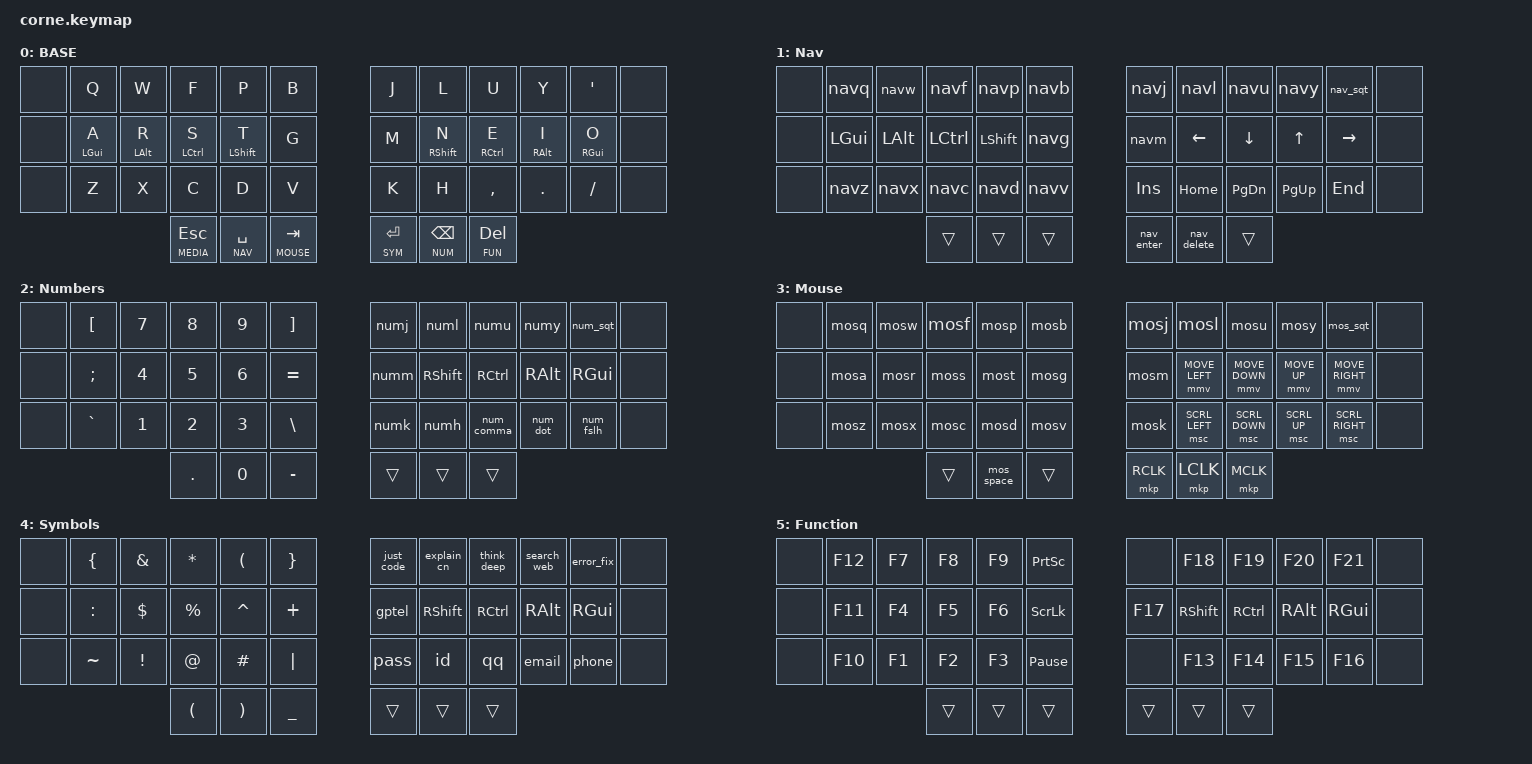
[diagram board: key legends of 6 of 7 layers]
#include <behaviors.dtsi>
#include <dt-bindings/zmk/keys.h>
#include <dt-bindings/zmk/outputs.h>
#include <dt-bindings/zmk/pointing.h>

#define ZMK_POINTING_DEFAULT_MOVE_VAL 450  // default: 600
#define ZMK_POINTING_DEFAULT_SCRL_VAL 20   // default: 10

#define BASE   0
#define NAV    1
#define NUM    2
#define MOUSE  3
#define SYM    4
#define FUN    5
#define MEDIA  6

#define QUICK_TAP_MS 145

&lt {
    flavor = "balanced";
    tapping-term-ms = <200>;
    quick-tap-ms = <QUICK_TAP_MS>;
};

&mmv {
    x-input-code             = <INPUT_REL_X>;
    y-input-code             = <INPUT_REL_Y>;
    time-to-max-speed-ms     = <0>;
    acceleration-exponent    = <0>;
};

&msc {
    x-input-code             = <INPUT_REL_HWHEEL>;
    y-input-code             = <INPUT_REL_WHEEL>;
    time-to-max-speed-ms     = <0>;
    acceleration-exponent    = <0>;
};

 / {

    macros {
    /* q  -> C-M-@  (Ctrl + Meta + @) */
    navq: navq {
        compatible = "zmk,behavior-macro";
        #binding-cells = <0>;
        bindings
        = <&macro_press   &kp LCTRL>
          , <&macro_tap     &kp LA(AT)>
          , <&macro_release &kp LCTRL>;
    };

    navw: navw {
        compatible = "zmk,behavior-macro";
        #binding-cells = <0>;
        /* w -> M-@ (Meta + @) */
        bindings = <&macro_tap     &kp LA(AT)>;
    };

    /* f -> C-M-h (Ctrl + Meta + h) */
    navf: navf {
        compatible = "zmk,behavior-macro";
        #binding-cells = <0>;
        bindings
        = <&macro_press   &kp LCTRL>
          , <&macro_tap     &kp LA(H)>
          , <&macro_release &kp LCTRL>;
    };

    /* p -> C-x h  (Ctrl+x then h) */
    navp: navp {
        compatible = "zmk,behavior-macro";
        #binding-cells = <0>;
        bindings
        = <&macro_tap     &kp LC(N)>
          , <&macro_tap     &kp H>;
    };

    /* b -> C-c, C-~, then B */
    navb: navb {
        compatible = "zmk,behavior-macro";
        #binding-cells = <0>;
        bindings
        = <&macro_tap     &kp LC(C)>
          , <&macro_tap     &kp LC(TILDE)>
          , <&macro_tap     &kp B>;
    };
////////
    navj: navj {
        compatible = "zmk,behavior-macro";
        #binding-cells = <0>;
        bindings
        = <&macro_tap     &kp LC(C)>
          , <&macro_tap     &kp LC(TILDE)>
          , <&macro_tap     &kp J>;
    };

    navl: navl {
        compatible = "zmk,behavior-macro";
        #binding-cells = <0>;
        bindings
        = <&macro_tap     &kp LC(C)>
          , <&macro_tap     &kp LC(TILDE)>
          , <&macro_tap     &kp L>;
    };

    navu: navu {
        compatible = "zmk,behavior-macro";
        #binding-cells = <0>;
        bindings
        = <&macro_tap     &kp LC(C)>
          , <&macro_tap     &kp LC(TILDE)>
          , <&macro_tap     &kp U>;
    };

    navy: navy {
        compatible = "zmk,behavior-macro";
        #binding-cells = <0>;
        bindings
        = <&macro_tap     &kp LC(C)>
          , <&macro_tap     &kp LC(TILDE)>
          , <&macro_tap     &kp Y>;
    };

    nav_sqt: nav_sqt {
        compatible = "zmk,behavior-macro";
        #binding-cells = <0>;
        bindings
        = <&macro_tap     &kp LC(C)>
          , <&macro_tap     &kp LC(TILDE)>
          , <&macro_tap     &kp SQT>;
    };


/////
    /* g: C-c, C-~, then g */
    navg: navg {
        compatible = "zmk,behavior-macro";
        #binding-cells = <0>;
        bindings
        = <&macro_tap     &kp LC(C)>
          , <&macro_tap     &kp LC(TILDE)>
          , <&macro_tap     &kp G>;
    };

    /* m: C-c, C-~, then m */
    navm: navm {
        compatible = "zmk,behavior-macro";
        #binding-cells = <0>;
        bindings
        = <&macro_tap     &kp LC(C)>
          , <&macro_tap     &kp LC(TILDE)>
          , <&macro_tap     &kp M>;
    };

    /* z -> C-x 0 */
    navz: navz {
        compatible = "zmk,behavior-macro";
        #binding-cells = <0>;
        bindings
      = <&macro_press &kp RCTRL>
        , <&macro_tap &kp N>
        , <&macro_release &kp RCTRL>
        , <&macro_tap &kp N0>;
    };

    /* x -> C-x 1 */
    navx: navx {
        compatible = "zmk,behavior-macro";
        #binding-cells = <0>;
        bindings
      = <&macro_press &kp RCTRL>
        , <&macro_tap &kp N>
        , <&macro_release &kp RCTRL>
        , <&macro_tap &kp N1>;
    };

    /* c -> C-x 2 */
    navc: navc {
        compatible = "zmk,behavior-macro";
        #binding-cells = <0>;
        bindings
      = <&macro_press &kp RCTRL>
        , <&macro_tap &kp N>
        , <&macro_release &kp RCTRL>
        , <&macro_tap &kp N2>;
    };

    /* d -> C-x o */
    navd: navd {
        compatible = "zmk,behavior-macro";
        #binding-cells = <0>;
        bindings
        = <&macro_tap     &kp LC(N)>
          , <&macro_tap     &kp O>;
    };

    /* v: C-c, C-~, then v */
    navv: navv {
        compatible = "zmk,behavior-macro";
        #binding-cells = <0>;
        bindings
        = <&macro_tap     &kp LC(C)>
          , <&macro_tap     &kp LC(TILDE)>
          , <&macro_tap     &kp V>;
    };

    /* enter -> M-g p   (Meta+g then p) */
    nav_enter: nav_enter {
        compatible = "zmk,behavior-macro";
        #binding-cells = <0>;
        bindings
        = <&macro_tap     &kp LA(G)>
          , <&macro_tap     &kp P>;
    };

    /* delete -> M-g n   (Meta+g then n) */
    nav_delete: nav_delete {
        compatible = "zmk,behavior-macro";
        #binding-cells = <0>;
        bindings
        = <&macro_tap     &kp LA(G)>
          , <&macro_tap     &kp N>;
    };

 /* Super + Shift + J */
numj: numj {
    compatible = "zmk,behavior-macro";
    #binding-cells = <0>;
    bindings = <&macro_tap   &kp LG(LS(J))>;
};

/* Super + Shift + L */
numl: numl {
    compatible = "zmk,behavior-macro";
    #binding-cells = <0>;
    bindings = <&macro_tap   &kp LG(LS(L))>;
};

/* Super + Shift + U */
numu: numu {
    compatible = "zmk,behavior-macro";
    #binding-cells = <0>;
    bindings = <&macro_tap   &kp LG(LS(U))>;
};

/* Super + Shift + Y */
numy: numy {
    compatible = "zmk,behavior-macro";
    #binding-cells = <0>;
    bindings = <&macro_tap   &kp LG(LS(Y))>;
};

/* Super + Shift + M */
numm: numm {
    compatible = "zmk,behavior-macro";
    #binding-cells = <0>;
    bindings = <&macro_tap   &kp LG(LS(M))>;
};

/* Super + Shift + K */
numk: numk {
    compatible = "zmk,behavior-macro";
    #binding-cells = <0>;
    bindings = <&macro_tap   &kp LG(LS(K))>;
};

/* Super + Shift + H */
numh: numh {
    compatible = "zmk,behavior-macro";
    #binding-cells = <0>;
    bindings = <&macro_tap   &kp LG(LS(H))>;
};

/* Super + Shift + COMMA (,) */
num_comma: num_comma {
    compatible = "zmk,behavior-macro";
    #binding-cells = <0>;
    bindings = <&macro_tap   &kp LG(LS(COMMA))>;
};

/* Super + Shift + DOT (.) */
num_dot: num_dot {
    compatible = "zmk,behavior-macro";
    #binding-cells = <0>;
    bindings = <&macro_tap   &kp LG(LS(DOT))>;
};

/* Super + Shift + FSLH (/) */
num_fslh: num_fslh {
    compatible = "zmk,behavior-macro";
    #binding-cells = <0>;
    bindings = <&macro_tap   &kp LG(LS(FSLH))>;
};

/* Super + Shift + SQT (') */
num_sqt: num_sqt {
    compatible = "zmk,behavior-macro";
    #binding-cells = <0>;
    bindings = <&macro_tap   &kp LG(LS(SQT))>;
};

/* -------------------------
   mos* macros (C-c, C-; , <key>)
   Use SEMI for ';'
   ------------------------- */

mosq: mosq {
    compatible = "zmk,behavior-macro";
    #binding-cells = <0>;
    bindings = <&macro_tap &kp LC(C)>, <&macro_tap &kp LC(SEMI)>, <&macro_tap &kp Q>;
};

mosw: mosw {
    compatible = "zmk,behavior-macro";
    #binding-cells = <0>;
    bindings = <&macro_tap &kp LC(C)>, <&macro_tap &kp LC(SEMI)>, <&macro_tap &kp W>;
};

mosf: mosf {
    compatible = "zmk,behavior-macro";
    #binding-cells = <0>;
    bindings = <&macro_tap &kp LC(C)>, <&macro_tap &kp LC(SEMI)>, <&macro_tap &kp F>;
};

mosp: mosp {
    compatible = "zmk,behavior-macro";
    #binding-cells = <0>;
    bindings = <&macro_tap &kp LC(C)>, <&macro_tap &kp LC(SEMI)>, <&macro_tap &kp P>;
};

/* b : C-x then C-b */
mosb: mosb {
    compatible = "zmk,behavior-macro";
    #binding-cells = <0>;
    bindings = <&macro_tap &kp LC(N)>, <&macro_tap &kp LC(B)>;
};

/* j/l -> C-c C-; <key> */
mosj: mosj {
    compatible = "zmk,behavior-macro";
    #binding-cells = <0>;
    bindings = <&macro_tap &kp LC(C)>, <&macro_tap &kp LC(SEMI)>, <&macro_tap &kp J>;
};

mosl: mosl {
    compatible = "zmk,behavior-macro";
    #binding-cells = <0>;
    bindings = <&macro_tap &kp LC(C)>, <&macro_tap &kp LC(SEMI)>, <&macro_tap &kp L>;
};

mosu: mosu {
    compatible = "zmk,behavior-macro";
    #binding-cells = <0>;
    bindings = <&macro_tap &kp LC(C)>, <&macro_tap &kp LC(SEMI)>, <&macro_tap &kp U>;
};

mosy: mosy {
    compatible = "zmk,behavior-macro";
    #binding-cells = <0>;
    bindings = <&macro_tap &kp LC(C)>, <&macro_tap &kp LC(SEMI)>, <&macro_tap &kp Y>;
};

mos_sqt: mos_sqt {
    compatible = "zmk,behavior-macro";
    #binding-cells = <0>;
    bindings = <&macro_tap &kp LC(C)>, <&macro_tap &kp LC(SEMI)>, <&macro_tap &kp SQT>;
};

mosa: mosa {
    compatible = "zmk,behavior-macro";
    #binding-cells = <0>;
    bindings = <&macro_tap &kp LC(N)>, <&macro_tap &kp LC(SEMI)>;
};

mosr: mosr {
    compatible = "zmk,behavior-macro";
    #binding-cells = <0>;
        bindings = <&macro_press &kp RCTRL>
        , <&macro_tap &kp G>
        , <&macro_release &kp RCTRL>;
};

moss: moss {
    compatible = "zmk,behavior-macro";
    #binding-cells = <0>;
    bindings = <&macro_press &kp RCTRL>
        , <&macro_tap &kp N>
        , <&macro_tap &kp F>
        , <&macro_release &kp RCTRL>;
};

most: most {
    compatible = "zmk,behavior-macro";
    #binding-cells = <0>;
    bindings = <&macro_tap &kp LC(N)>, <&macro_tap &kp B>;
};

mosg: mosg {
    compatible = "zmk,behavior-macro";
    #binding-cells = <0>;
    bindings = <&macro_tap &kp LC(N)>, <&macro_tap &kp G>;
};

mosm: mosm {
    compatible = "zmk,behavior-macro";
    #binding-cells = <0>;
    bindings = <&macro_tap &kp LC(C)>, <&macro_tap &kp LC(SEMI)>, <&macro_tap &kp M>;
};

mosz: mosz {
    compatible = "zmk,behavior-macro";
    #binding-cells = <0>;
    bindings = <&macro_tap &kp LA(S)>, <&macro_tap &kp DOT>;
};

mosx: mosx {
    compatible = "zmk,behavior-macro";
    #binding-cells = <0>;
    /* Ctrl+Alt+Shift+5  -> nested wrappers produce the same */
    bindings = <&macro_tap &kp LC(LA(PRCNT))>;
};

mosc: mosc {
    compatible = "zmk,behavior-macro";
    #binding-cells = <0>;
    bindings = <&macro_tap &kp LC(C)>, <&macro_tap &kp LC(SEMI)>, <&macro_tap &kp C>;
};

mosd: mosd {
    compatible = "zmk,behavior-macro";
    #binding-cells = <0>;
    bindings = <&macro_tap &kp LC(N)>, <&macro_tap &kp D>;
};

mosv: mosv {
    compatible = "zmk,behavior-macro";
    #binding-cells = <0>;
    bindings = <&macro_tap &kp LC(C)>, <&macro_tap &kp LC(SEMI)>, <&macro_tap &kp V>;
};

mosk: mosk {
    compatible = "zmk,behavior-macro";
    #binding-cells = <0>;
    bindings = <&macro_tap &kp LC(N)>, <&macro_tap &kp K>;
};

mos_space: mos_space {
    compatible = "zmk,behavior-macro";
    #binding-cells = <0>;
    bindings = <&macro_tap &kp LC(N)>, <&macro_tap &kp TAB>;
};

just_code: just_code {
        compatible = "zmk,behavior-macro";
        #binding-cells = <0>;
        bindings = <
            &macro_tap
                &kp J &kp U &kp S &kp T &kp UNDERSCORE &kp G &kp I &kp V &kp E &kp UNDERSCORE
                &kp M &kp E &kp UNDERSCORE &kp T &kp H &kp E &kp UNDERSCORE &kp C &kp O &kp D &kp E &kp EXCL
        >;
    };

    explain_cn: explain_cn {
        compatible = "zmk,behavior-macro";
        #binding-cells = <0>;
        bindings = <
            &macro_tap
                &kp E &kp X &kp P &kp L &kp A &kp I &kp N &kp UNDERSCORE &kp I &kp N &kp UNDERSCORE &kp C &kp H &kp I &kp N &kp E &kp S &kp E &kp EXCL
        >;
    };

    think_deep: think_deep {
        compatible = "zmk,behavior-macro";
        #binding-cells = <0>;
        bindings = <
            &macro_tap
                &kp T &kp H &kp I &kp N &kp K &kp UNDERSCORE &kp L &kp O &kp N &kp G &kp E &kp R &kp EXCL
        >;
    };

    search_web: search_web {
        compatible = "zmk,behavior-macro";
        #binding-cells = <0>;
        bindings = <
            &macro_tap
                &kp S &kp E &kp A &kp R &kp C &kp H &kp UNDERSCORE &kp T &kp H &kp E &kp UNDERSCORE &kp W &kp E &kp B &kp EXCL
        >;
    };

    error_fix: error_fix {
        compatible = "zmk,behavior-macro";
        #binding-cells = <0>;
        bindings = <
            &macro_tap
                &kp E &kp R &kp R &kp O &kp R &kp UNDERSCORE &kp F &kp I &kp X &kp UNDERSCORE &kp I &kp T &kp EXCL
        >;
    };

     gptel: gptel {
         compatible = "zmk,behavior-macro";
         #binding-cells = <0>;
         bindings =<&macro_tap &kp LG(M)>;
     };

pass: pass {
    compatible = "zmk,behavior-macro";
    #binding-cells = <0>;
    bindings = <
        &macro_tap
        &kp LS(D)   /* Shift + d = capital D */
        &kp A
        &kp X
        &kp U
        &kp E
        &kp M
        &kp I
        &kp M
        &kp A
        &kp N3
        &kp N2
        &kp N1
        &kp DOT
    >;
};

    qq: qq_macro {
        compatible = "zmk,behavior-macro";
        #binding-cells = <0>;
        bindings
            = <&macro_tap &kp N2 &kp N7 &kp N3 &kp N0 &kp N6 &kp N4 &kp N7 &kp N0 &kp N5 &kp N2>;
    };

    id: id_macro {
        compatible = "zmk,behavior-macro";
        #binding-cells = <0>;
        bindings
            = <&macro_tap
                &kp N5 &kp N0 &kp N0 &kp N1 &kp N1 &kp N2 &kp N2 &kp N0 &kp N0 &kp N2 &kp N1 &kp N1
                &kp N0 &kp N4 &kp N0 &kp N9 &kp N9 &kp KP_MULTIPLY>;
    };

    email: email_macro {
        compatible = "zmk,behavior-macro";
        #binding-cells = <0>;
        bindings
            = <&macro_tap
                &kp G &kp T &kp K &kp N &kp D &kp C &kp B &kp F &kp H &kp R
                &kp AT &kp G &kp M &kp A &kp I &kp L &kp DOT &kp C &kp O &kp M>;
    };

    phone: phone_macro {
        compatible = "zmk,behavior-macro";
        #binding-cells = <0>;
        bindings
            = <&macro_tap &kp N1 &kp N3 &kp N3 &kp N0 &kp N8 &kp N3 &kp N2 &kp N9 &kp N2 &kp N4 &kp N2>;
    };
};

    behaviors {
        hm: homerow_mods {
            compatible               = "zmk,behavior-hold-tap";
            #binding-cells           = <2>;
            tapping-term-ms          = <250>;
            quick-tap-ms             = <QUICK_TAP_MS>;
            flavor                   = "balanced";
            require-prior-idle-ms    = <130>;
            // hold-trigger-on-release;  / 只有松开后才触发 Hold，减少意外连击
            bindings                 = <&kp>, <&kp>;
        };
    };

    conditional_layers {
        compatible = "zmk,conditional-layers";
    };

    keymap {
        compatible = "zmk,keymap";

        BASE {
            bindings = <
                &none   &kp Q          &kp W          &kp F          &kp P          &kp B         &kp J          &kp L         &kp U         &kp Y         &kp SQT     &none
                &none   &hm LGUI A     &hm LALT R     &hm LCTRL S    &hm LSHIFT T   &kp G         &kp M          &hm RSHIFT N  &hm RCTRL E   &hm RALT I    &hm RGUI O  &none
                &none   &kp Z          &kp X          &kp C          &kp D          &kp V         &kp K          &kp H         &kp COMMA     &kp DOT       &kp FSLH    &none
                                  &lt MEDIA ESC  &lt NAV SPACE  &lt MOUSE TAB  &lt SYM RET  &lt NUM BSPC  &lt FUN DEL
            >;
        };

// copy/down/up/fullscreen/toggle/ cduftabr
        Nav {
            bindings = <
                &none   &navq        &navw        &navf        &navp        &navb        &navj    &navl   &navu    &navy    &nav_sqt  &none
                &none   &kp LGUI     &kp LALT     &kp LCTRL    &kp LSHIFT   &navg        &navm         &kp LEFT    &kp DOWN      &kp UP        &kp RIGHT   &none
                &none   &navz        &navx        &navc        &navd        &navv        &kp INSERT    &kp HOME    &kp PG_DN     &kp PG_UP     &kp END     &none
                                    &trans       &trans       &trans       &nav_enter       &nav_delete       &trans
            >;
        };

        Numbers {
            bindings = <
                &none   &kp LBKT      &kp N7      &kp N8      &kp N9      &kp RBKT     &numj       &numl      &numu      &numy      &num_sqt      &none
                &none   &kp SEMI      &kp N4      &kp N5      &kp N6      &kp EQUAL    &numm       &kp RSHIFT &kp RCTRL  &kp RALT   &kp RGUI   &none
              &none   &kp GRAVE     &kp N1      &kp N2      &kp N3      &kp BSLH     &numk         &numh       &num_comma       &num_dot       &num_fslh       &none
                                        &kp DOT    &kp N0      &kp MINUS   &trans      &trans      &trans
            >;
        };

        Mouse {
            bindings = <
                &none   &mosq    &mosw  &mosf  &mosp     &mosb     &mosj       &mosl         &mosu       &mosy      &mos_sqt      &none
                &none   &mosa   &mosr      &moss    &most     &mosg         &mosm       &mmv MOVE_LEFT  &mmv MOVE_DOWN  &mmv MOVE_UP  &mmv MOVE_RIGHT  &none
                &none   &mosz   &mosx    &mosc    &mosd     &mosv         &mosk &msc SCRL_LEFT  &msc SCRL_DOWN  &msc SCRL_UP  &msc SCRL_RIGHT  &none
                                            &trans     &mos_space     &trans      &mkp RCLK   &mkp LCLK   &mkp MCLK
            >;
        };

        Symbols {
            bindings = <
                &none   &kp LBRC      &kp AMPS     &kp ASTRK   &kp LPAR     &kp RBRC     &just_code       &explain_cn       &think_deep       &search_web       &error_fix       &none
                &none   &kp COLON     &kp DLLR     &kp PRCNT   &kp CARET    &kp PLUS     &gptel       &kp RSHIFT  &kp RCTRL   &kp RALT    &kp RGUI    &none
                &none   &kp TILDE     &kp EXCL     &kp AT      &kp HASH     &kp PIPE     &pass       &id      &qq      &email &phone  &none
                                        &kp LPAR     &kp RPAR    &kp UNDER   &trans      &trans      &trans
            >;
        };

        Function {
            bindings = <
                &none   &kp F12      &kp F7      &kp F8      &kp F9      &kp PRINTSCREEN &none  &kp F18     &kp F19      &kp F20      &kp F21          &none
                &none   &kp F11      &kp F4      &kp F5      &kp F6      &kp SCROLLLOCK   &kp F17   &kp RSHIFT  &kp RCTRL   &kp RALT    &kp RGUI      &none
                &none   &kp F10      &kp F1      &kp F2      &kp F3      &kp PAUSE_BREAK  &none    &kp F13      &kp F14      &kp F15      &kp F16      &none
                                         &trans   &trans   &trans      &trans          &trans      &trans
            >;
        };

        media {
            bindings = <
                &none   &none      &none      &none      &none      &none         &kp C_REWIND    &none      &none      &none      &kp C_FAST_FORWARD  &none
                &none   &kp LGUI   &kp LALT   &kp LCTRL  &kp LSHIFT &none         &kp C_PREVIOUS  &kp C_VOL_DN  &kp C_VOLUME_UP  &kp C_NEXT  &none
                &none   &none      &none      &none      &none      &none         &out OUT_TOG    &kp LANGUAGE_5  &none   &none   &none   &none
                                      &trans   &trans   &trans    &kp C_PLAY_PAUSE  &kp C_STOP  &kp C_MUTE
            >;
        };
    };
};
